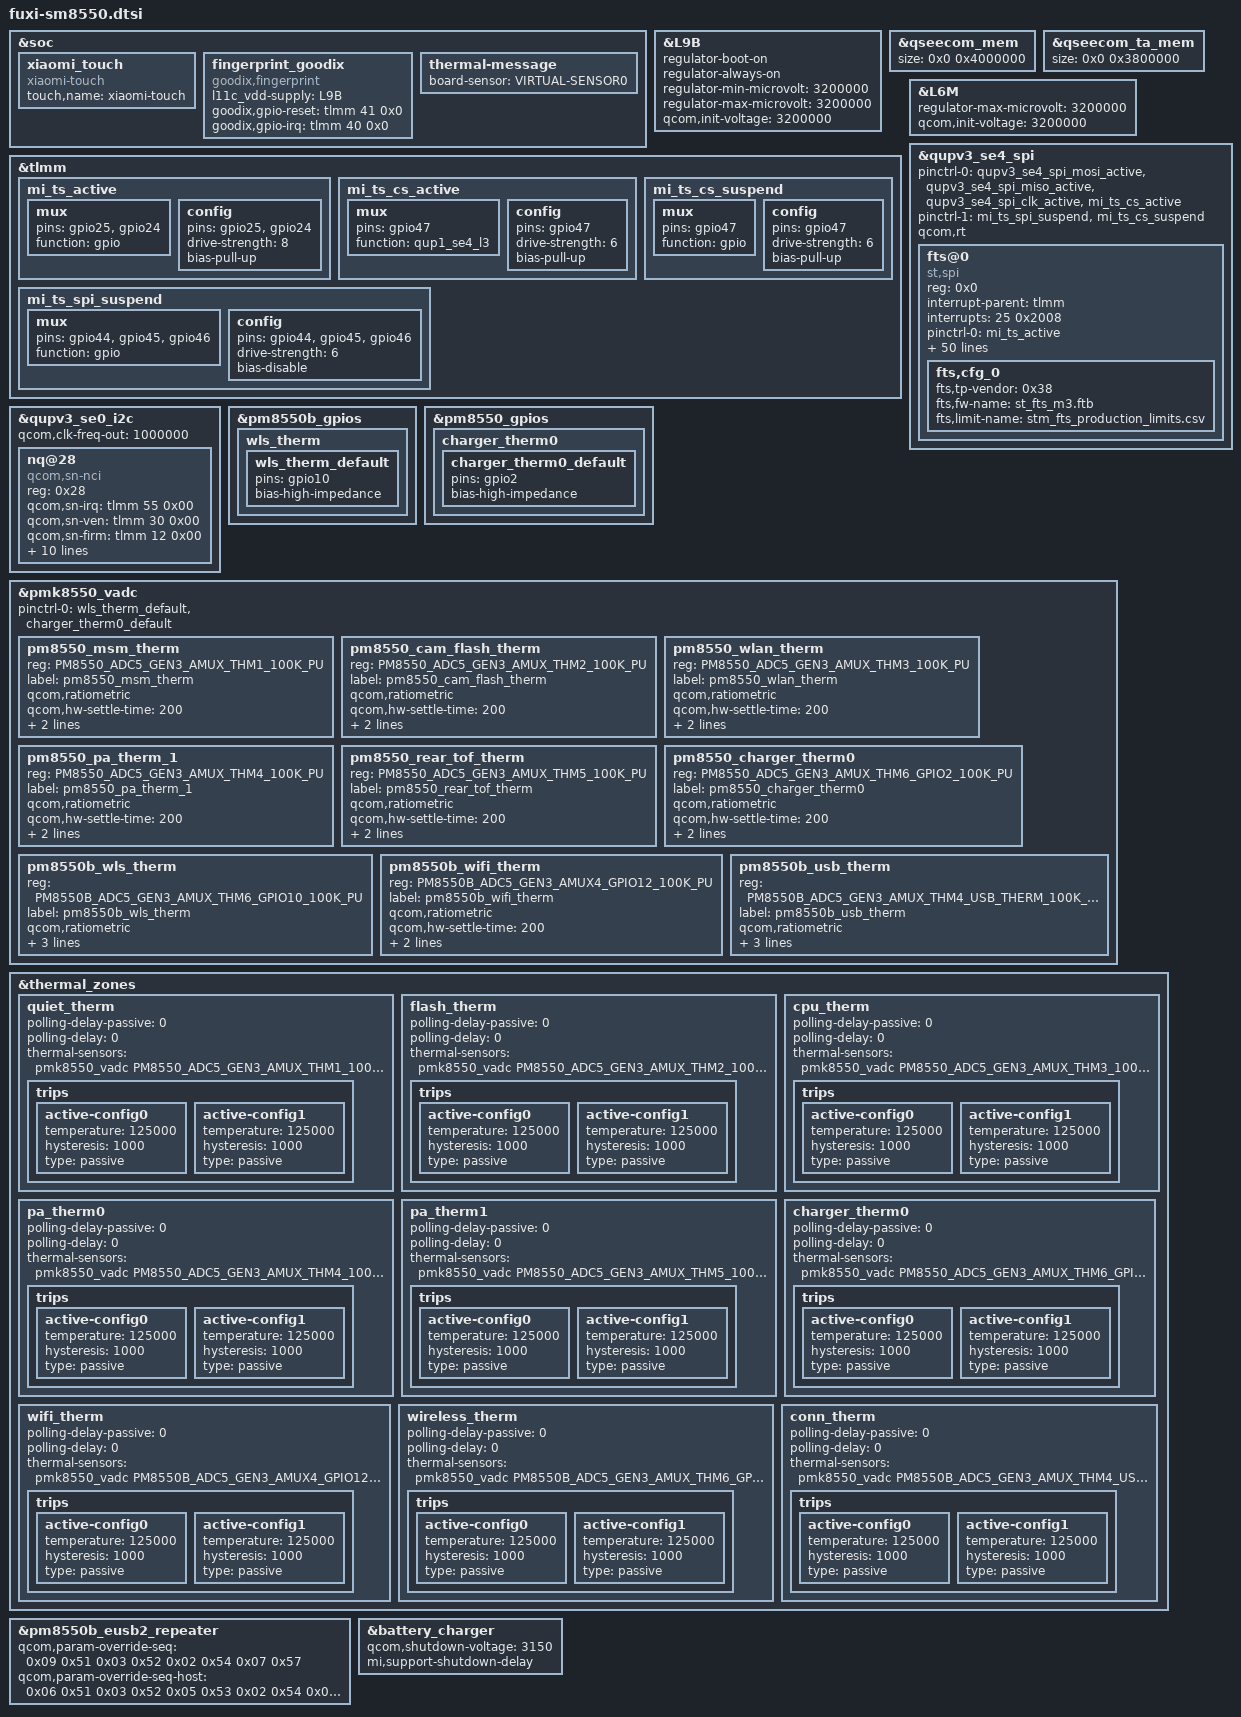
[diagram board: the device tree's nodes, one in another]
/*
  this file is for attribution only of zeus
  And public attribution of xiaomi platforms(like M2 and so and)
*/

#define FUXI_NUWA_REGULATOR_OCP
#include "fuxi-pinctrl.dtsi"
#include "xiaomi-sm8550-common.dtsi"
#include <dt-bindings/clock/qcom,rpmh.h>

&soc {
	xiaomi_touch {
		compatible = "xiaomi-touch";
		status = "ok";
		touch,name = "xiaomi-touch";
	};
	fingerprint_goodix {
		compatible = "goodix,fingerprint";
		l11c_vdd-supply = <&L9B>;
		goodix,gpio-reset = <&tlmm 41 0x0>;
		goodix,gpio-irq = <&tlmm 40 0x0>;
		status = "ok";
	};
};

&L9B {
	regulator-boot-on;
	regulator-always-on;
	regulator-min-microvolt = <3200000>;
	regulator-max-microvolt = <3200000>;
	qcom,init-voltage = <3200000>;
};

&qseecom_mem {
		size = <0x0 0x4000000>;
};

&qseecom_ta_mem {
		size = <0x0 0x3800000>;
};

&tlmm {
	mi_ts_active: mi_ts_active {
		mux {
				pins = "gpio25", "gpio24";
				function = "gpio";
		};

		config {
				pins = "gpio25", "gpio24";
				drive-strength = <8>;
				bias-pull-up;
		};
	};

	mi_ts_cs_active: mi_ts_cs_active {
		mux {
			pins = "gpio47";
			function = "qup1_se4_l3";
		};

		config {
			pins = "gpio47";
			drive-strength = <6>;
			bias-pull-up;
		};
	};

	mi_ts_cs_suspend: mi_ts_cs_suspend {
		mux {
			pins = "gpio47";
			function = "gpio";
		};

		config {
			pins = "gpio47";
			drive-strength = <6>;
			bias-pull-up;
		};
	};

	mi_ts_spi_suspend: mi_ts_spi_suspend {
		mux {
			pins = "gpio44", "gpio45", "gpio46";
			function = "gpio";
		};

		config {
			pins = "gpio44", "gpio45", "gpio46";
			drive-strength = <6>;
			bias-disable;
		};
	};
};

&L6M {
	regulator-max-microvolt = <3200000>;
	qcom,init-voltage = <3200000>;
};

&qupv3_se4_spi {
	status = "ok";
	pinctrl-0 = <&qupv3_se4_spi_mosi_active>, <&qupv3_se4_spi_miso_active>,
				<&qupv3_se4_spi_clk_active>, <&mi_ts_cs_active>;
	pinctrl-1 = <&mi_ts_spi_suspend &mi_ts_cs_suspend>;
	qcom,rt;
	fts@0 {
		status = "ok";
		compatible = "st,spi";
		reg = <0x0>;
		interrupt-parent = <&tlmm>;
		interrupts = <25 0x2008>;
		pinctrl-names = "pmx_ts_active", "pmx_ts_suspend";
		pinctrl-0 = <&mi_ts_active>;
		pinctrl-1 = <&ts_int_suspend &ts_reset_suspend>;
		avdd-supply = <&L6M>;
		vdd-supply = <&L12B>;
		/*panel = <&dsi_k8_42_02_0a_dsc_cmd>;*/
		fts,pwr-reg-name = "avdd";
		fts,bus-reg-name = "vdd";
		fts,irq-gpio = <&tlmm 25 0x2008>;
		fts,irq-gpio-name = "fts_irq";
		fts,reset-gpio-enable;
		fts,reset-gpio = <&tlmm 24 0x00>;
		fts,reset-gpio-name = "fts_rst";
		fts,irq-flags = <0x2008>;
		fts,x-max = <10800>;
		fts,y-max = <24000>;
		fts,fod-lx = <4420>;
		fts,fod-ly = <20520>;
		fts,fod-x-size = <1960>;
		fts,fod-y-size = <1960>;
		fts,support-fod;
		spi-max-frequency = <12000000>;
		fts,support-super-resolution = <1>;
		fts,default-fw-name = "st_fts_m3.ftb";
		fts,config-array-size = <1>;
		fts,touch-follow-performance-def = <3>;
		fts,touch-tap-sensitivity-def = <4>;
		fts,touch-aim-sensitivity-def = <3>;
		fts,touch-tap-stability-def = <3>;
		fts,cornerfilter-area-step1 = <100>;
		fts,cornerfilter-area-step2 = <170>;
		fts,cornerfilter-area-step3 = <250>;
		fts,touch-deadzone-filter-ver = <2 0 0 0 0 0 0 0
										2 1 0 0 0 0 0 0
										2 2 0 0 0 0 0 0
										2 3 0 0 0 0 0 0>;
		fts,touch-deadzone-filter-hor = <2 0 0 0 0 0 0 0
										2 1 0 0 0 0 0 0
										2 2 0 0 0 0 0 0
										2 3 0 0 0 0 0 0>;
		fts,touch-edgezone-filter-ver = <1 0 0 0 0 0 0 0
										1 1 0 0 0 0 0 0
										1 2 0 0 50 2399 0 0
										1 3 1029 0 1079 2399 0 0>;
		fts,touch-edgezone-filter-hor = <1 0 0 0 1079 50 0 0
										1 1 0 2349 1079 2399 0 0
										1 2 0 0 50 2399 0 0
										1 3 1029 0 1079 2399 0 0>;
		fts,touch-cornerzone-filter-ver = <0 0 0 0 0 0 0 0
										0 1 0 0 0 0 0 0
										0 2 0 2249 300 2399 0 0
										0 3 929 2099 1079 2399 0 0>;
		fts,touch-cornerzone-filter-hor1 = <0 0 0 0 170 170 0 0
										0 1 0 0 0 0 0 0
										0 2 0 2229 170 2399 0 0
										0 3 0 0 0 0 0 0>;
		fts,touch-cornerzone-filter-hor2 = <0 0 0 0 0 0 0 0
										0 1 909 0 1079 170 0 0
										0 2 0 0 0 0 0 0
										0 3 909 2229 1079 2399 0 0>;
		fts,touch-follow-performance = <10 15 1
										8 15 1
										6 15 1
										4 15 1
										2 15 1>;
		fts,touch-tap-sensitivity = <160 150 140 120 100>;
		fts,touch-aim-sensitivity = <10 8 6 4 2>;
		fts,touch-tap-stability = <8 12 15 18 25>;
		fts,touch-expert-array = <6 15 1 120 6 15
								  2 15 1 120 4 15
								  4 15 1 120 2 15>;
		fts,cfg_0 {
			fts,tp-vendor = <0x38>;
			fts,fw-name = "st_fts_m3.ftb";
			fts,limit-name = "stm_fts_production_limits.csv";
		};
	};
};

&qupv3_se0_i2c {
	status = "ok";
	qcom,clk-freq-out = <1000000>;
	#address-cells = <1>;
	#size-cells = <0>;
	nq@28 {
		compatible = "qcom,sn-nci";
		reg = <0x28>;
		qcom,sn-irq = <&tlmm 55 0x00>;
		qcom,sn-ven = <&tlmm 30 0x00>;
		qcom,sn-firm = <&tlmm 12 0x00>;
		qcom,sn-clkreq = <&tlmm 31 0x00>;
		qcom,sn-szone = "enable";
		qcom,sn-vdd-1p8-supply = <&L15B>;
		qcom,sn-vdd-1p8-voltage = <1760000 1800000>;
		qcom,sn-vdd-1p8-current = <157000>;
		interrupt-parent = <&tlmm>;
		interrupts = <55 0>;
		interrupt-names = "nfc_irq";
		pinctrl-names = "nfc_active", "nfc_suspend";
		pinctrl-0 = <&nfc_int_active &nfc_enable_active>;
		pinctrl-1 = <&nfc_int_suspend &nfc_enable_suspend>;
		/* clocks only need for Kailua V1 device */
		clocks = <&rpmhcc RPMH_LN_BB_CLK2>;
		clock-names = "nfc_ref_clk";
	};
};

&pm8550b_gpios {
	wls_therm {
		wls_therm_default: wls_therm_default {
		pins = "gpio10";
		bias-high-impedance;
	};
	};
};

&pm8550_gpios {
	charger_therm0 {
		charger_therm0_default: charger_therm0_default {
		pins = "gpio2";
		bias-high-impedance;
	};
	};
};

&pmk8550_vadc {
	pinctrl-names = "default";
	pinctrl-0 = <&wls_therm_default>, <&charger_therm0_default>;
	pm8550_msm_therm {
		reg = <PM8550_ADC5_GEN3_AMUX_THM1_100K_PU>;
		label = "pm8550_msm_therm";
		qcom,ratiometric;
		qcom,hw-settle-time = <200>;
		qcom,pre-scaling = <1 1>;
		qcom,adc-tm-type = <1>;
	};

	pm8550_cam_flash_therm {
		reg = <PM8550_ADC5_GEN3_AMUX_THM2_100K_PU>;
		label = "pm8550_cam_flash_therm";
		qcom,ratiometric;
		qcom,hw-settle-time = <200>;
		qcom,pre-scaling = <1 1>;
		qcom,adc-tm-type = <1>;
	};

	pm8550_wlan_therm {
		reg = <PM8550_ADC5_GEN3_AMUX_THM3_100K_PU>;
		label = "pm8550_wlan_therm";
		qcom,ratiometric;
		qcom,hw-settle-time = <200>;
		qcom,pre-scaling = <1 1>;
		qcom,adc-tm-type = <1>;
	};

	pm8550_pa_therm_1 {
		reg = <PM8550_ADC5_GEN3_AMUX_THM4_100K_PU>;
		label = "pm8550_pa_therm_1";
		qcom,ratiometric;
		qcom,hw-settle-time = <200>;
		qcom,pre-scaling = <1 1>;
		qcom,adc-tm-type = <1>;
	};

	pm8550_rear_tof_therm {
		reg = <PM8550_ADC5_GEN3_AMUX_THM5_100K_PU>;
		label = "pm8550_rear_tof_therm";
		qcom,ratiometric;
		qcom,hw-settle-time = <200>;
		qcom,pre-scaling = <1 1>;
		qcom,adc-tm-type = <1>;
	};

	pm8550_charger_therm0 {
		reg = <PM8550_ADC5_GEN3_AMUX_THM6_GPIO2_100K_PU>;
		label = "pm8550_charger_therm0";
		qcom,ratiometric;
		qcom,hw-settle-time = <200>;
		qcom,pre-scaling = <1 1>;
		qcom,adc-tm-type = <1>;
	};

	pm8550b_wls_therm {
		reg = <PM8550B_ADC5_GEN3_AMUX_THM6_GPIO10_100K_PU>;
		label = "pm8550b_wls_therm";
		qcom,ratiometric;
		qcom,hw-settle-time = <200>;
		qcom,pre-scaling = <1 1>;
		qcom,adc-tm-type = <1>;
	};

	pm8550b_wifi_therm {
		reg = <PM8550B_ADC5_GEN3_AMUX4_GPIO12_100K_PU>;
		label = "pm8550b_wifi_therm";
		qcom,ratiometric;
		qcom,hw-settle-time = <200>;
		qcom,pre-scaling = <1 1>;
		qcom,adc-tm-type = <1>;
	};

	pm8550b_usb_therm {
		reg = <PM8550B_ADC5_GEN3_AMUX_THM4_USB_THERM_100K_PU>;
		label = "pm8550b_usb_therm";
		qcom,ratiometric;
		qcom,hw-settle-time = <200>;
		qcom,pre-scaling = <1 1>;
		qcom,adc-tm-type = <1>;
	};
};

&thermal_zones {
	quiet_therm {
		polling-delay-passive = <0>;
		polling-delay = <0>;
		thermal-sensors = <&pmk8550_vadc PM8550_ADC5_GEN3_AMUX_THM1_100K_PU>;
		trips {
			active-config0 {
				temperature = <125000>;
				hysteresis = <1000>;
				type = "passive";
			};

			active-config1 {
				temperature = <125000>;
				hysteresis = <1000>;
				type = "passive";
			};
		};
	};

	flash_therm {
		polling-delay-passive = <0>;
		polling-delay = <0>;
		thermal-sensors = <&pmk8550_vadc PM8550_ADC5_GEN3_AMUX_THM2_100K_PU>;
		trips {
			active-config0 {
				temperature = <125000>;
				hysteresis = <1000>;
				type = "passive";
			};

			active-config1 {
				temperature = <125000>;
				hysteresis = <1000>;
				type = "passive";
			};
		};
	};

	cpu_therm {
		polling-delay-passive = <0>;
		polling-delay = <0>;
		thermal-sensors = <&pmk8550_vadc PM8550_ADC5_GEN3_AMUX_THM3_100K_PU>;
		trips {
			active-config0 {
				temperature = <125000>;
				hysteresis = <1000>;
				type = "passive";
			};

			active-config1 {
				temperature = <125000>;
				hysteresis = <1000>;
				type = "passive";
			};
		};
	};

	pa_therm0 {
		polling-delay-passive = <0>;
		polling-delay = <0>;
		thermal-sensors = <&pmk8550_vadc PM8550_ADC5_GEN3_AMUX_THM4_100K_PU>;
		trips {
			active-config0 {
				temperature = <125000>;
				hysteresis = <1000>;
				type = "passive";
			};

			active-config1 {
				temperature = <125000>;
				hysteresis = <1000>;
				type = "passive";
			};
		};
	};

	pa_therm1 {
		polling-delay-passive = <0>;
		polling-delay = <0>;
		thermal-sensors = <&pmk8550_vadc PM8550_ADC5_GEN3_AMUX_THM5_100K_PU>;
		trips {
			active-config0 {
				temperature = <125000>;
				hysteresis = <1000>;
				type = "passive";
			};

			active-config1 {
				temperature = <125000>;
				hysteresis = <1000>;
				type = "passive";
			};
		};
	};

	charger_therm0 {
		polling-delay-passive = <0>;
		polling-delay = <0>;
		thermal-sensors = <&pmk8550_vadc PM8550_ADC5_GEN3_AMUX_THM6_GPIO2_100K_PU>;
		trips {
			active-config0 {
				temperature = <125000>;
				hysteresis = <1000>;
				type = "passive";
			};

			active-config1 {
				temperature = <125000>;
				hysteresis = <1000>;
				type = "passive";
			};
		};
	};

	wifi_therm {
		polling-delay-passive = <0>;
		polling-delay = <0>;
		thermal-sensors = <&pmk8550_vadc PM8550B_ADC5_GEN3_AMUX4_GPIO12_100K_PU>;
		trips {
			active-config0 {
				temperature = <125000>;
				hysteresis = <1000>;
				type = "passive";
			};

			active-config1 {
				temperature = <125000>;
				hysteresis = <1000>;
				type = "passive";
			};
		};
	};

	wireless_therm {
		polling-delay-passive = <0>;
		polling-delay = <0>;
		thermal-sensors = <&pmk8550_vadc PM8550B_ADC5_GEN3_AMUX_THM6_GPIO10_100K_PU>;
		trips {
			active-config0 {
				temperature = <125000>;
				hysteresis = <1000>;
				type = "passive";
			};

			active-config1 {
				temperature = <125000>;
				hysteresis = <1000>;
				type = "passive";
			};
		};
	};

	conn_therm {
		polling-delay-passive = <0>;
		polling-delay = <0>;
		thermal-sensors = <&pmk8550_vadc PM8550B_ADC5_GEN3_AMUX_THM4_USB_THERM_100K_PU>;
		trips {
			active-config0 {
				temperature = <125000>;
				hysteresis = <1000>;
				type = "passive";
			};

			active-config1 {
				temperature = <125000>;
				hysteresis = <1000>;
				type = "passive";
			};
		};
	};
};

&soc {
	thermal-message {
		board-sensor = "VIRTUAL-SENSOR0";
	};
};

&pm8550b_eusb2_repeater {
	qcom,param-override-seq =
		<0x09 0x51
		0x03 0x52
		0x02 0x54
		0x07 0x57>;
	qcom,param-override-seq-host =
		<0x06 0x51
		0x03 0x52
		0x05 0x53
		0x02 0x54
		0x00 0x55
		0x04 0x57>;
};

&battery_charger {
	qcom,shutdown-voltage = <3150>;
	mi,support-shutdown-delay;
};
